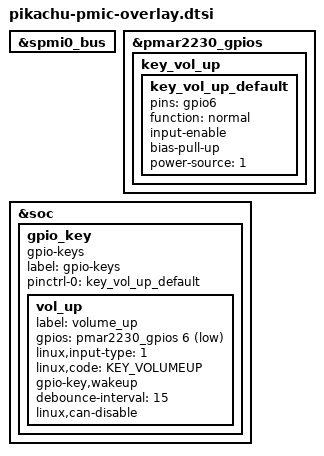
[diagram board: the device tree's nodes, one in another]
// SPDX-License-Identifier: BSD-3-Clause
/*
 * Copyright (c) Qualcomm Technologies, Inc. and/or its subsidiaries.
 */

#include <dt-bindings/gpio/gpio.h>
#include <dt-bindings/input/input.h>

&spmi0_bus {
	#include "pm8010.dtsi"
	#include "pmar2230.dtsi"
	#include "pmg1110.dtsi"
};

&pmar2230_gpios {
	key_vol_up {
		key_vol_up_default: key_vol_up_default {
			pins = "gpio6";
			function = "normal";
			input-enable;
			bias-pull-up;
			power-source = <1>;
		};
	};
};

&soc {
	gpio_key {
		compatible = "gpio-keys";
		label = "gpio-keys";
		pinctrl-names = "default";
		pinctrl-0 = <&key_vol_up_default>;

		vol_up {
			label = "volume_up";
			gpios = <&pmar2230_gpios 6 GPIO_ACTIVE_LOW>;
			linux,input-type = <1>;
			linux,code = <KEY_VOLUMEUP>;
			gpio-key,wakeup;
			debounce-interval = <15>;
			linux,can-disable;
		};
	};
};
